AUTOSAR XML (schema 4-2-2)
package /Components
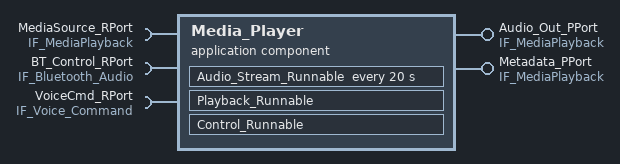
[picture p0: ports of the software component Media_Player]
  application sw component type Media_Player
    provide port Audio_Out_PPort: provided-interface=IF_MediaPlayback
    provide port Metadata_PPort: provided-interface=IF_MediaPlayback
    require port MediaSource_RPort: required-interface=IF_MediaPlayback
    require port BT_Control_RPort: required-interface=IF_Bluetooth_Audio
    require port VoiceCmd_RPort: required-interface=IF_Voice_Command
    behavior Media_Player_Behavior
      data write completed event Buffer_Write_Completed: start-on-event=Audio_Stream_Runnable, event-source=Send_DecodedAudio
      timing event Playback_Timer: start-on-event=Audio_Stream_Runnable, period=20
      runnable Playback_Runnable: minimum-start-interval=20, symbol=Media_Player_Playback_Runnable
        data-receive-point-by-arguments:
          access Recv_AudioChunk: accessed-variable=MediaSource_RPort.AudioStream
        data-send-points:
          access Send_DecodedAudio: accessed-variable=Audio_Out_PPort.DecodedAudioFrame
      runnable Control_Runnable: minimum-start-interval=200, symbol=Media_Player_Control_Runnable
        data-receive-point-by-arguments:
          access Recv_ControlCmd: accessed-variable=VoiceCmd_RPort.VoiceCommand
        data-send-points:
          access Send_Metadata: accessed-variable=Metadata_PPort.Metadata
        async call BT_Control_Call: operation=BT_Control_RPort.BtControl, timeout=1000
